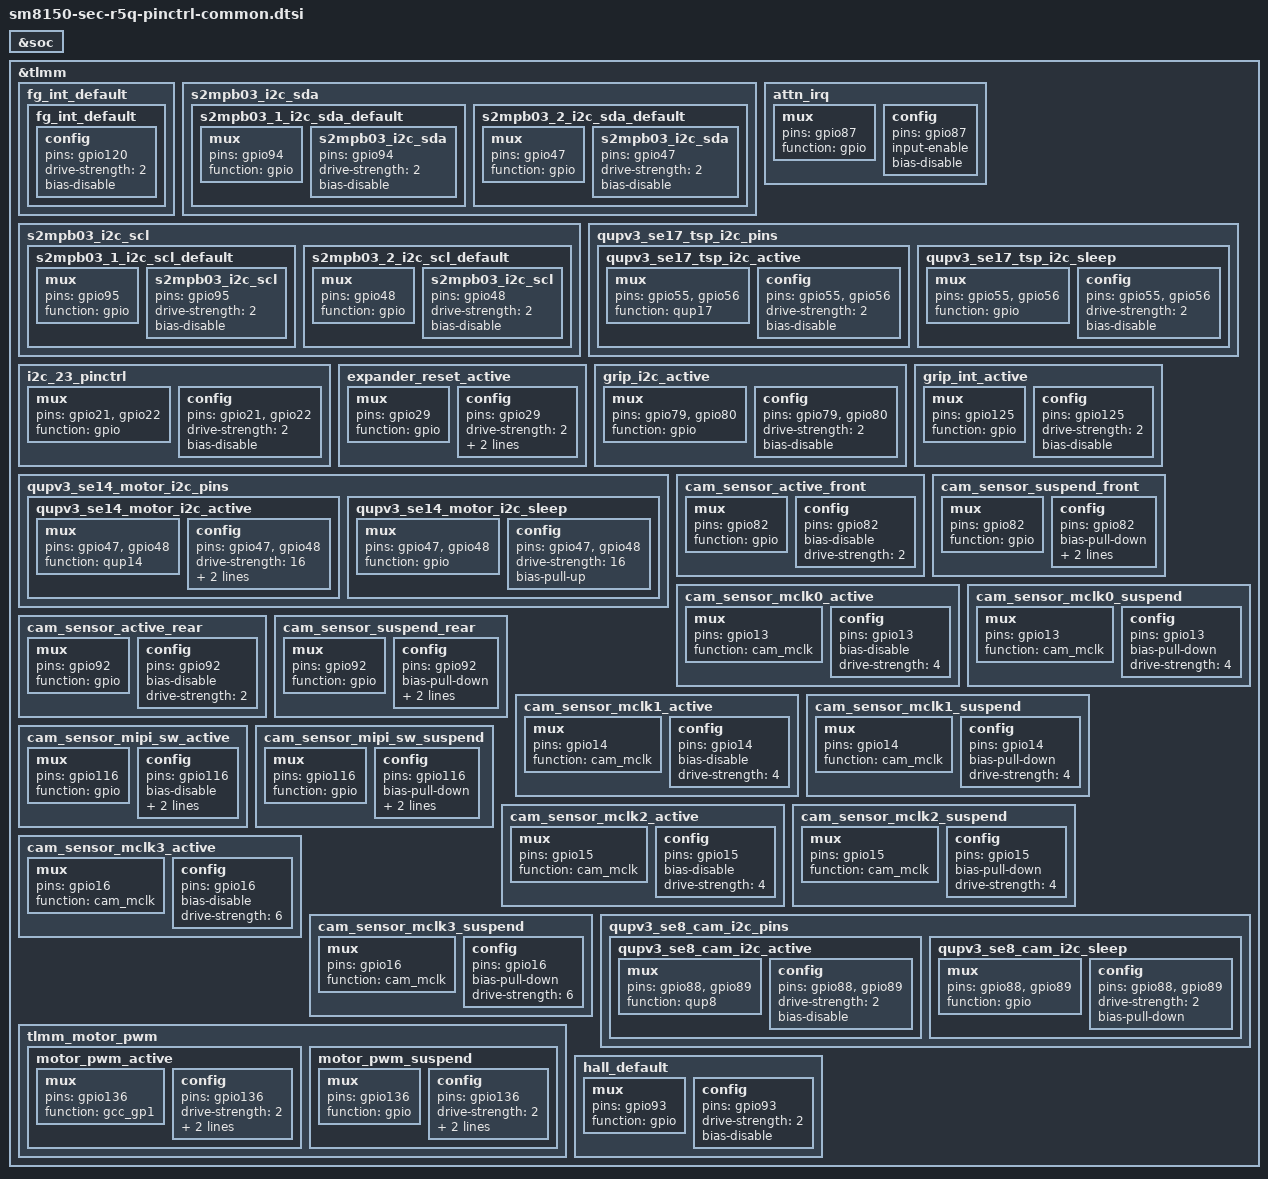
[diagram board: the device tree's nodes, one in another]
/* Copyright (c) 2016-2018, The Linux Foundation. All rights reserved.
 *
 * This program is free software; you can redistribute it and/or modify
 * it under the terms of the GNU General Public License version 2 and
 * only version 2 as published by the Free Software Foundation.
 *
 * This program is distributed in the hope that it will be useful,
 * but WITHOUT ANY WARRANTY; without even the implied warranty of
 * MERCHANTABILITY or FITNESS FOR A PARTICULAR PURPOSE.  See the
 * GNU General Public License for more details.
 */

#include "sm8150-sec-r5q-audio-pinctrl.dtsi"

&soc {
};

&tlmm {
	fg_int_default {
		fg_int_default: fg_int_default {
			config {
				pins = "gpio120";
				drive-strength = <2>;
				bias-disable;
			};
		};
	};

	s2mpb03_i2c_sda {
		s2mpb03_1_i2c_sda_default: s2mpb03_1_i2c_sda_default {
			mux {
				pins = "gpio94";
				function = "gpio";
			};
			s2mpb03_i2c_sda {
				pins = "gpio94";
				drive-strength = <2>;
				bias-disable;
			};
		};

		s2mpb03_2_i2c_sda_default: s2mpb03_2_i2c_sda_default {
			mux {
				pins = "gpio47";
				function = "gpio";
			};
			s2mpb03_i2c_sda {
				pins = "gpio47";
				drive-strength = <2>;
				bias-disable;
			};
		};
	};
	s2mpb03_i2c_scl {
		s2mpb03_1_i2c_scl_default: s2mpb03_1_i2c_scl_default {
			mux {
				pins = "gpio95";
				function = "gpio";
			};
			s2mpb03_i2c_scl {
				pins = "gpio95";
				drive-strength = <2>;
				bias-disable;
			};
		};

		s2mpb03_2_i2c_scl_default: s2mpb03_2_i2c_scl_default {
			mux {
				pins = "gpio48";
				function = "gpio";
			};
			s2mpb03_i2c_scl {
				pins = "gpio48";
				drive-strength = <2>;
				bias-disable;
			};
		};
	};

	attn_irq: attn_irq {
		mux {
			pins = "gpio87";
			function = "gpio";
		};
		config {
			pins = "gpio87";
			input-enable;
			bias-disable;
		};
	};

#if 0
	muic_i2c {
		muic_i2c_active: muic_i2c_active {
			muic_i2c {
				pins = "gpio25", "gpio26";
				drive-strength = <2>;
				bias-disable;
			};
		};
		muic_i2c_suspend: muic_i2c_suspend {
			muic_i2c {
				pins = "gpio25", "gpio26";
				drive-strength = <2>;
				bias-disable;
			};
		};
	};
#endif
	/* SE 17 pin mappings */
	qupv3_se17_tsp_i2c_pins: qupv3_se17_tsp_i2c_pins {
		qupv3_se17_tsp_i2c_active: qupv3_se17_tsp_i2c_active {
			mux {
				pins = "gpio55", "gpio56";
				function = "qup17";
			};

			config {
				pins = "gpio55", "gpio56";
				drive-strength = <2>;
				bias-disable;
			};
		};

		qupv3_se17_tsp_i2c_sleep: qupv3_se17_tsp_i2c_sleep {
			mux {
				pins = "gpio55", "gpio56";
				function = "gpio";
			};

			config {
				pins = "gpio55", "gpio56";
				drive-strength = <2>;
				bias-disable;
			};
		};
	};

	i2c_23_pinctrl: i2c_23_pinctrl {
		mux {
			pins = "gpio21",	/* EXPANDER_I2C_SDA_1P8 */
			       "gpio22";	/* EXPANDER_I2C_SCL_1P8 */
			function = "gpio";
		};
		config {
			pins = "gpio21",	/* EXPANDER_I2C_SDA_1P8 */
			       "gpio22";	/* EXPANDER_I2C_SCL_1P8 */
			drive-strength = <2>;
			bias-disable;
		};
	};

	expander_reset_active: expander_reset_active {
		mux {
			pins = "gpio29";
			function = "gpio";
		};
		config {
			pins = "gpio29";
			drive-strength = <2>;   /* 16 mA */
			bias-disable;
			output-high;
		};
	};

	grip_i2c_active: grip_i2c_active {
		mux {
			pins = "gpio79", "gpio80";
			function = "gpio";
		};
		config {
			pins = "gpio79", "gpio80";
			drive-strength = <2>;
			bias-disable;
		};
	};

	grip_int_active: grip_int_active {
		mux {
			pins = "gpio125";
			function = "gpio";
		};
		config {
			pins = "gpio125";
			drive-strength = <2>;
			bias-disable;
		};
	};

	/delete-node/ qupv3_se14_i2c_pins;

	qupv3_se14_motor_i2c_pins: qupv3_se14_motor_i2c_pins {
		qupv3_se14_motor_i2c_active: qupv3_se14_motor_i2c_active {
			mux {
				pins = "gpio47", "gpio48";
				function = "qup14";
			};

			config {
				pins = "gpio47", "gpio48";
				drive-strength = <16>;
				output-high;
				bias-disable;
			};
		};

		qupv3_se14_motor_i2c_sleep: qupv3_se14_motor_i2c_sleep {
			mux {
				pins = "gpio47", "gpio48";
				function = "gpio";
			};

			config {
				pins = "gpio47", "gpio48";
				drive-strength = <16>;
				bias-pull-up;
			};
		};
	};

	cam_sensor_active_front: cam_sensor_active_front {
		/* RESET FRONT */
		mux {
			pins = "gpio82";
			function = "gpio";
		};

		config {
			pins = "gpio82";
			bias-disable; /* No PULL */
			drive-strength = <2>; /* 2 MA */
		};
	};

	cam_sensor_suspend_front: cam_sensor_suspend_front {
		/* RESET FRONT */
		mux {
			pins = "gpio82";
			function = "gpio";
		};

		config {
			pins = "gpio82";
			bias-pull-down; /* PULL DOWN */
			drive-strength = <2>; /* 2 MA */
			output-low;
		};
	};

	cam_sensor_mclk0_active: cam_sensor_mclk0_active {
                /* MCLK0 */
                mux {
                        pins = "gpio13";
                        function = "cam_mclk";
                };
                config {
                        pins = "gpio13";
                        bias-disable; /* No PULL */
                        drive-strength = <4>; /* 4 MA */
                };
        };

        cam_sensor_mclk0_suspend: cam_sensor_mclk0_suspend {
                /* MCLK0 */
                mux {
                        pins = "gpio13";
                        function = "cam_mclk";
                };
                config {
                        pins = "gpio13";
                        bias-pull-down; /* PULL DOWN */
                        drive-strength = <4>; /* 4 MA */
                };
        };

        cam_sensor_active_rear: cam_sensor_active_rear {
                /* RESET REAR */
                mux {
                        pins = "gpio92";
                        function = "gpio";
                };
                config {
                        pins = "gpio92";
                        bias-disable; /* No PULL */
                        drive-strength = <2>; /* 2 MA */
                };
        };

        cam_sensor_suspend_rear: cam_sensor_suspend_rear {
                /* RESET REAR */
                mux {
                        pins = "gpio92";
                        function = "gpio";
                };
                config {
                        pins = "gpio92";
                        bias-pull-down; /* PULL DOWN */
                        drive-strength = <2>; /* 2 MA */
                        output-low;
                };
        };
        cam_sensor_mclk1_active: cam_sensor_mclk1_active {
                /* MCLK1 */
                mux {
                        pins = "gpio14";
                        function = "cam_mclk";
                };
                config {
                        pins = "gpio14";
                        bias-disable; /* No PULL */
                        drive-strength = <4>; /* 4 MA */
                };
        };

        cam_sensor_mclk1_suspend: cam_sensor_mclk1_suspend {
                /* MCLK1 */
                mux {
                        pins = "gpio14";
                        function = "cam_mclk";
                };
                config {
                        pins = "gpio14";
                        bias-pull-down; /* PULL DOWN */
                        drive-strength = <4>; /* 4 MA */
                };
        };
        cam_sensor_mipi_sw_active: cam_sensor_mipi_sw_active {
		/* MIPI_SW */
		mux {
			pins = "gpio116";
			function = "gpio";
		};
		config {
			pins = "gpio116";
			bias-disable; /* No PULL */
			output-high;
			drive-strength = <2>; /* 2 MA */
		};
	};

	cam_sensor_mipi_sw_suspend: cam_sensor_mipi_sw_suspend {
		/* MIPI_SW */
		mux {
			pins = "gpio116";
			function = "gpio";
		};
		config {
			pins = "gpio116";
			bias-pull-down;
			drive-strength = <2>; /* 2 MA */
			output-low;
		};
	};

	cam_sensor_mclk2_active: cam_sensor_mclk2_active {
		/* MCLK2 */
		mux {
			pins = "gpio15";
			function = "cam_mclk";
		};

		config {
			pins = "gpio15";
			bias-disable; /* No PULL */
			drive-strength = <4>; /* 4 MA */
		};
	};

	cam_sensor_mclk2_suspend: cam_sensor_mclk2_suspend {
		/* MCLK2 */
		mux {
			pins = "gpio15";
			function = "cam_mclk";
		};

		config {
			pins = "gpio15";
			bias-pull-down; /* PULL DOWN */
			drive-strength = <4>; /* 4 MA */
		};
	};

	cam_sensor_mclk3_active: cam_sensor_mclk3_active {
		/* MCLK3 */
		mux {
			pins = "gpio16";
			function = "cam_mclk";
		};

		config {
			pins = "gpio16";
			bias-disable; /* No PULL */
			drive-strength = <6>; /* 6 MA */
		};
	};

	cam_sensor_mclk3_suspend: cam_sensor_mclk3_suspend {
		/* MCLK3 */
		mux {
			pins = "gpio16";
			function = "cam_mclk";
		};

		config {
			pins = "gpio16";
			bias-pull-down; /* PULL DOWN */
			drive-strength = <6>; /* 6 MA */
		};
	};

	qupv3_se8_cam_i2c_pins: qupv3_se8_cam_i2c_pins {
		qupv3_se8_cam_i2c_active: qupv3_se8_cam_i2c_active {
			mux {
				pins = "gpio88", "gpio89";
				function = "qup8";
			};

			config {
				pins = "gpio88", "gpio89";
				drive-strength = <2>;
				bias-disable;
			};
		};	
		qupv3_se8_cam_i2c_sleep: qupv3_se8_cam_i2c_sleep {
			mux {
				pins = "gpio88", "gpio89";
				function = "gpio";
			};

			config {
				pins = "gpio88", "gpio89";
				drive-strength = <2>;
				bias-pull-down;
			};
		};
	};

	/* add pinctrl for motor  */
	tlmm_motor_pwm {
		motor_pwm_active: motor_pwm_active {
			mux {
				pins = "gpio136";
				function = "gcc_gp1";
			};
			config {
				pins = "gpio136";
				drive-strength = <2>;   /* 16 mA */
				bias-disable;
				output-high;
			};
		};
		motor_pwm_suspend: motor_pwm_suspend {
			mux {
				pins = "gpio136";
				function = "gpio";
			};
			config {
				pins = "gpio136";
				drive-strength = <2>;   /* 16 mA */
				bias-disable;
				output-low;
			};
		};
	};

	hall_default: hall_default {
		mux {
			pins = "gpio93";
			function = "gpio";
		};
		config {
			pins = "gpio93";
			drive-strength = <2>;
			bias-disable;
		};
	};
};
